# CY8C6347BZI_BLD33 register map
File version: 0.1
PSoC 63
Registers are 32-bit, read-write, no defined reset value unless marked. A register's access mark holds for its fields unless they carry their own. Offsets are from the block's base; lines under a group give offsets from that group; [hi:lo] are bit positions; {n}, {i} and the like mark numbered series; 'fields as' and 'values as' point back to an identical list; <NAME> marks a mode.

## Memory map
0x00000000 SMIF_1
0x00000000 CapSense

## SMIF_1
Base 0x00000000
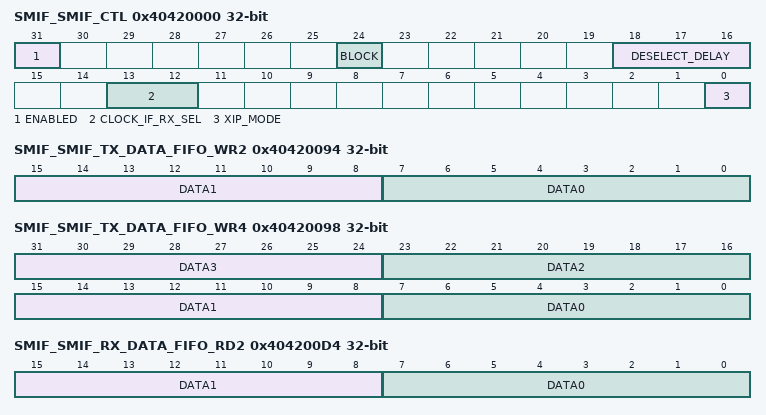
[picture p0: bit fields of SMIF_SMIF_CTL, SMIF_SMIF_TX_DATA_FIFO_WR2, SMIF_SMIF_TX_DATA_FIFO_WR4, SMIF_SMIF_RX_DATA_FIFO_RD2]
0x40420000 SMIF_SMIF_CTL — Control
  [31] ENABLED — IP enable:?'0': Disabled. All non-retention registers are reset to their default value when the IP is disabled. When the IP is disabled, the XIP accesses produce AHB-Lite bus errors.?'1': Enabled.??Note: Before disabling the IP, SW should ensure that the IP is NOT busy (STATUS.BUSY is '0'), otherwise illegal interface transfers may occur.
    0=DISABLED; 1=ENABLED
  [24] BLOCK — Specifies what happens for MMIO interface read accesses to an empty RX data FIFO or to a full TX format/data FIFO. Note: the FIFOs can only be accessed in MMIO_MODE.??This field is not used for test controller accesses.
    0=BUS_ERROR (0': Generate an AHB-Lite bus error. This option is useful when SW decides to use polling on STATUS.TR_BUSY to determine if a interface transfer is no longer busy (transfer is completed). This option adds SW complexity, but limits the number of AHB-Lite wait states (and limits ISR latency).); 1=WAIT_STATES (1': Introduce wait states. This setting potentially locks up the AHB-Lite infrastructure and may increase the CPU interrupt latency.This option is useful when SW performs TX/RX data FIFO accesses immediately after a command is setup using the TX format FIFO. This option has low SW complexity, but may result in a significant number of AHB-Lite wait states (and may increase ISR latency).)
  [18:16] DESELECT_DELAY — Specifies the minimum duration of SPI deselection ("spi_select_out[]" is high/'1') in between SPI transfers:?"0": 1 interface clock cycle.?"1": 2 interface clock cycles.?"2": 3 interface clock cycles.?"3": 4 interface clock cycles.?"4": 5 interface clock cycles.?"5": 6 interface clock cycles.?"6": 7 interface clock cycles.?"7": 8 interface clock cycles.??During SPI deselection, "spi_select_out[]" are '1'/inactive, "spi_data_out[]" are '1' and "spi_clk_out" is '0'/inactive.
  [13:12] CLOCK_IF_RX_SEL — Specifies device interface receiver clock "clk_if_rx" source. MISO data is captured on the rising edge of "clk_if_rx".?"0": "spi_clk_out" (internal clock)?"1": !"spi_clk_out" (internal clock)?"2": "spi_clk_in" (feedback clock)?"3": !"spi_clk_in" (feedback clock)??Note: the device interface transmitter clock "clk_if_tx" is fixed and is "spi_clk_out" MOSI data is driven on the falling edge of "clk_if_tx".
  [0] XIP_MODE — Mode of operation.??Note: this field should only be changed when the IP is disabled or when STATUS.BUSY is '0' and SW should not be executing from the XIP interface or MMIO interface.
    0=MMIO_MODE ('0': MMIO mode. Individual MMIO accesses to TX and RX FIFOs are used to generate a sequence of SPI transfers. This mode of operation allows for large flexibility in terms of the SPI transfers that can be generated.); 1=XIP_MODE (1': XIP mode. eXecute-In-Place mode: incoming read and write transfers over the AHB-Lite bus infrastructure are automatically translated in SPI transfers to read data from and write data to a device. This mode of operation allow for efficient device read and write operations. This mode is only supported in SPI_MODE.)
0x40420004 SMIF_SMIF_STATUS — Status
  [31] BUSY ro — Cache, cryptography, XIP, device interface or any other logic busy in the IP:?'0': not busy?'1': busy?When BUSY is '0', the IP can be safely disabled without:?- the potential loss of transient write data.?- the potential risk of aborting an inflight SPI device interface transfer.?When BUSY is '0', the mode of operation (XIP_MODE or MMIO_MODE) can be safely changed.
0x40420044 SMIF_SMIF_TX_CMD_FIFO_STATUS — Transmitter command FIFO status
  [2:0] USED3 ro — Number of entries that are used in the TX command FIFO (available in both XIP_MODE and MMIO_MODE). Legal range: [0, 4].
0x40420050 SMIF_SMIF_TX_CMD_FIFO_WR — Transmitter command FIFO write
  [19:0] DATA20 wo — Command data. The higher two bits DATA[19:18] specify the specific command?"0"/TX: A SPI transfer always start with a TX command FIFO entry of the ?TX? format.?- DATA[17:16] specifies the width of the data transfer:? - "0": 1 bit/cycle (single data transfer).? - "1": 2 bits/cycle (dual data transfer).? - "2": 4 bits/cycle (quad data transfer).? - "3": 8 bits/cycle (octal data transfer).?- DATA[15]: specifies whether this is the last TX Byte; i.e. whether the ?spi_select_out[3:0]? IO output signals are de-activated after the transfer.?- DATA[11:8] specifies which of the four devices are selected. DATA[11:8] are directly mapped to "spi_select_out[3:0]". Two devices can be selected at the same time in dual-quad mode.? - '0': device deselected? - '1': device selected ?- DATA[7:0] specifies the transmitted Byte.??"1"/TX_COUNT: The ?TX_COUNT? command relies on the TX data FIFO to provide the transmitted bytes. The "TX_COUNT" command is ALWAYS considered to be the last command of a SPI data transfers.?- DATA[17:16] specifies the width of the transfer.?- DATA[15:0] specifies the number of to be transmitted Bytes (minus 1) from the TX data FIFO.??"2"/RX_COUNT: The ?RX_COUNT? command relies on the RX data FIFO to accept the received bytes. The "RX_COUNT" command is ALWAYS considered to be the last command of a SPI data transfers.?- DATA[17:16] specifies the width of the transfer.?- DATA[15:0] specifies the number of to be transmitted Bytes (minus 1) to the RX data FIFO.??"3"/DUMMY_COUNT: The "DUMMY_COUNT" command conveys dummy cycles. Dummy cycles are used to implement a Turn-Around time in which the SPI master changes from a transmitter driving the data lines to a receiver receiving on the same data lines. The "DUMMY_COUNT" command is ALWAYS considered to be NOT the last command of a SPI data transfers; i.e. it needs to be followed by another command.?- DATA[15:0] specifies the number of dummy cycles (minus 1). In dummy cycles, the data lines are not driven.
0x40420080 SMIF_SMIF_TX_DATA_FIFO_CTL — Transmitter data FIFO control
  [2:0] TRIGGER_LEVEL — Determines when the TX data FIFO "tr_tx_req" trigger is activated (trigger activation requires MMIO_MODE, the trigger is NOT activated in XIP_MODE):?- Trigger is active when TX_DATA_FIFO_STATUS.USED <= TRIGGER_LEVEL.
0x40420084 SMIF_SMIF_TX_DATA_FIFO_STATUS — Transmitter data FIFO status
  [3:0] USED4 ro — Number of entries that are used in the TX data FIFO (available in both XIP_MODE and MMIO_MODE). Legal range: [0, 8].
0x40420090 SMIF_SMIF_TX_DATA_FIFO_WR1 — Transmitter data FIFO write
  [7:0] DATA0 wo — TX data (written to TX data FIFO).
0x40420094 SMIF_SMIF_TX_DATA_FIFO_WR2 — Transmitter data FIFO write
  [15:8] DATA1 wo — TX data (written to TX data FIFO, second byte).
  [7:0] DATA0 wo — TX data (written to TX data FIFO, first byte).
0x40420098 SMIF_SMIF_TX_DATA_FIFO_WR4 — Transmitter data FIFO write
  [31:24] DATA3 wo — TX data (written to TX data FIFO, fourth byte).
  [23:16] DATA2 wo — TX data (written to TX data FIFO, third byte).
  [15:8] DATA1 wo — TX data (written to TX data FIFO, second byte).
  [7:0] DATA0 wo — TX data (written to TX data FIFO, first byte).
0x404200C0 SMIF_SMIF_RX_DATA_FIFO_CTL — Receiver data FIFO control
  [2:0] TRIGGER_LEVEL — Determines when RX data FIFI "tr_rx_req" trigger is activated (trigger activation requires MMIO_MODE, the trigger is NOT activated in XIP_MODE):?- Trigger is active when RX_DATA_FIFO_STATUS.USED > TRIGGER_LEVEL.
0x404200C4 SMIF_SMIF_RX_DATA_FIFO_STATUS — Receiver data FIFO status
  [3:0] USED4 ro — Number of entries that are used in the RX data FIFO (available in both XIP_MODE and MMIO_MODE). Legal range: [0, 8].
0x404200D0 SMIF_SMIF_RX_DATA_FIFO_RD1 — Receiver data FIFO read
  [7:0] DATA0 ro — RX data (read from RX data FIFO).
0x404200D4 SMIF_SMIF_RX_DATA_FIFO_RD2 — Receiver data FIFO read
  [15:8] DATA1 ro — RX data (read from RX data FIFO, second byte).
  [7:0] DATA0 ro — RX data (read from RX data FIFO, first byte).
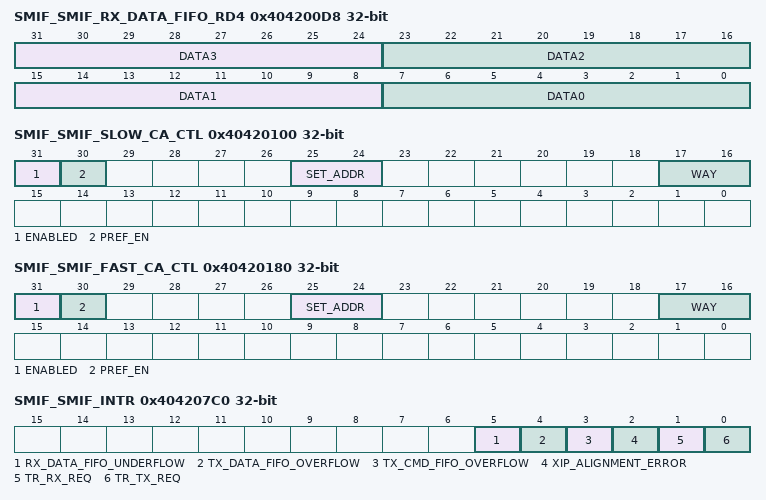
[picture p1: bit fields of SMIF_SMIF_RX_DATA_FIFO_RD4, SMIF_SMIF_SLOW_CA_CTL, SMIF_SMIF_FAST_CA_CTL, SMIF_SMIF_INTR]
0x404200D8 SMIF_SMIF_RX_DATA_FIFO_RD4 — Receiver data FIFO read
  [31:24] DATA3 ro — RX data (read from RX data FIFO, fourth byte).
  [23:16] DATA2 ro — RX data (read from RX data FIFO, third byte).
  [15:8] DATA1 ro — RX data (read from RX data FIFO, second byte).
  [7:0] DATA0 ro — RX data (read from RX data FIFO, first byte).
0x404200E0 SMIF_SMIF_RX_DATA_FIFO_RD1_SILENT — Receiver data FIFO silent read
  [7:0] DATA0 ro — RX data (read from RX data FIFO).
0x40420100 SMIF_SMIF_SLOW_CA_CTL — Slow cache control
  [31] ENABLED — Cache enable:?'0': Disabled.?'1': Enabled.
  [30] PREF_EN — Prefetch enable:?'0': Disabled.?'1': Enabled.??Prefetching requires the cache to be enabled; i.e. ENABLED is '1'.
  [25:24] SET_ADDR — Specifies the cache set for which cache information is provided in SLOW_CA_STATUS0/1/2.
  [17:16] WAY — Specifies the cache way for which cache information is provided in SLOW_CA_STATUS0/1/2.
0x40420108 SMIF_SMIF_SLOW_CA_CMD — Slow cache command
  [0] INV — Cache invalidation. SW writes a '1' to clear the cache. The cache's LRU structure is also reset to its default state.
0x40420140 SMIF_SMIF_SLOW_CA_STATUS0 — Slow cache status 0
  [15:0] VALID16 ro — Sixteen valid bits of the cache line specified by SLOW_CA_CTL.WAY and SLOW_CA_CTL.SET_ADDR.
0x40420144 SMIF_SMIF_SLOW_CA_STATUS1 — Slow cache status 1
  [31:0] TAG ro — Cache line address of the cache line specified by SLOW_CA_CTL.WAY and SLOW_CA_CTL.SET_ADDR.
0x40420148 SMIF_SMIF_SLOW_CA_STATUS2 — Slow cache status 2
  [5:0] LRU ro — Six bit LRU representation of the cache set specified by SLOW_CA_CTL.SET_ADDR. The encoding of the field is as follows ("X_LRU_Y" indicates that way X is Less Recently Used than way Y):?Bit 5: 0_LRU_1: way 0 less recently used than way 1.?Bit 4: 0_LRU_2.?Bit 3: 0_LRU_3.?Bit 2: 1_LRU_2.?Bit 1: 1_LRU_3.?Bit 0: 2_LRU_3.
0x40420180 SMIF_SMIF_FAST_CA_CTL — Fast cache control
  [31] ENABLED — See SLOW_CA_CTL.ENABLED.
  [30] PREF_EN — See SLOW_CA_CTL.PREF_EN.
  [25:24] SET_ADDR — See SLOW_CA_CTL.SET_ADDR.
  [17:16] WAY — See SLOW_CA_CTL.WAY.
0x40420188 SMIF_SMIF_FAST_CA_CMD — Fast cache command
  [0] INV — See SLOW_CA_CMD.INV.
0x404201C0 SMIF_SMIF_FAST_CA_STATUS0 — Fast cache status 0
  [15:0] VALID16 ro — See SLOW_CA_STATUS0.VALID16.
0x404201C4 SMIF_SMIF_FAST_CA_STATUS1 — Fast cache status 1
  [31:0] TAG ro — See SLOW_CA_STATUS1.TAG.
0x404201C8 SMIF_SMIF_FAST_CA_STATUS2 — Fast cache status 2
  [5:0] LRU ro — See SLOW_CA_STATUS2.LRU.
0x40420200 SMIF_SMIF_CRYPTO_CMD — Cryptography Command
  [0] START — SW sets this field to '1' to start a AES-128 forward block cipher operation (on the address in CRYPTO_ADDR). HW sets this field to '0' to indicate that the operation has completed. Once completed, the result of the operation can be read from CRYPTO_RESULT0, ..., CRYPTO_RESULT3.??The operation takes roughly 13 clk_hf clock cycles.??Note: An operation can only be started in MMIO_MODE.
{0x40420220+4i} SMIF_SMIF_CRYPTO_INPUT{i} (i=0..3) — Cryptography input {i}
  [31:0] INPUT — Four Bytes of the plaintext PT[{32i+31}:{32i}] = CRYPTO_INPUT{i}.INPUT[31:0].
{0x40420240+4i} SMIF_SMIF_CRYPTO_KEY{i} (i=0..3) — Cryptography key {i}
  [31:0] KEY wo — Four Bytes of the key KEY[{32i+31}:{32i}] = CRYPTO_KEY{i}.KEY[31:0].
{0x40420260+4i} SMIF_SMIF_CRYPTO_OUTPUT{i} (i=0..3) — Cryptography output {i}
  [31:0] OUTPUT — Four Bytes of the ciphertext CT[{32i+31}:{32i}] = CRYPTO_OUTPUT{i}.OUTPUT[31:0].
0x404207C0 SMIF_SMIF_INTR — Interrupt register
  [5] RX_DATA_FIFO_UNDERFLOW — Activated in MMIO mode, on an AHB-Lite read transfer from the RX data FIFO (RX_DATA_FIFO_RD1, RX_DATA_FIFO_RD2, RX_DATA_FIFO_RD4) with not enough entries available. Only activated for NON test bus controller transfers.
  [4] TX_DATA_FIFO_OVERFLOW — Activated in MMIO mode, on an AHB-Lite write transfer to the TX data FIFO (TX_DATA_FIFO_WR1, TX_DATA_FIFO_WR2, TX_DATA_FIFO_WR4) with not enough free entries available.
  [3] TX_CMD_FIFO_OVERFLOW — Activated in MMIO mode, on an AHB-Lite write transfer to the TX command FIFO (TX_CMD_FIFO_WR) with not enough free entries available.
  [2] XIP_ALIGNMENT_ERROR — Activated in XIP mode, if:?- The selected device's ADDR_CTL.DIV2 is '1' and the AHB-Lite bus transfer address is not a multiple of 2.?- The selected device's ADDR_CTL.DIV2 is '1' and the XIP transfer request is NOT for a multiple of 2 Bytes. ??Note: In dual-quad SPI mode (ADDR_CTL.DIV is '1'), each memory device contributes a 4-bit nibble for read data or write data. This is only possible if the request address is a multiple of 2 and the number of requested Bytes is a multiple of 2.
  [1] TR_RX_REQ — Activated in MMIO mode, when a RX data FIFO trigger "tr_rx_req" is activated.
  [0] TR_TX_REQ — Activated in MMIO mode, when a TX data FIFO trigger "tr_tx_req" is activated.
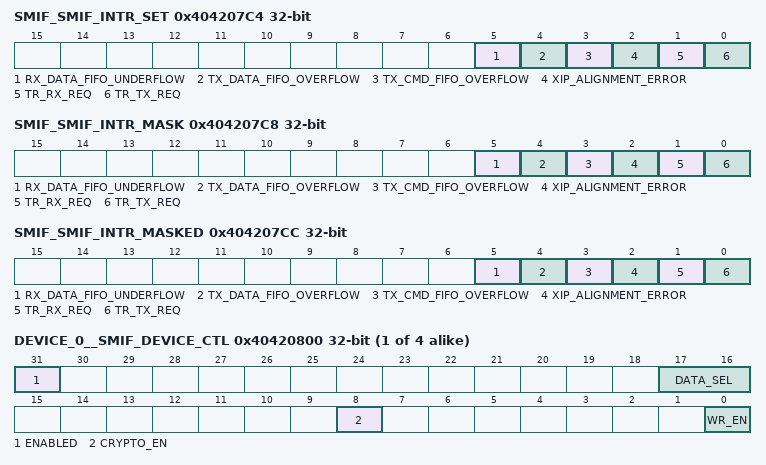
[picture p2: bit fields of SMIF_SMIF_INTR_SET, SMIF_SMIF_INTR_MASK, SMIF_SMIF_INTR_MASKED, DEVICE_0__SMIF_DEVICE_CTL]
0x404207C4 SMIF_SMIF_INTR_SET — Interrupt set register
  [5] RX_DATA_FIFO_UNDERFLOW — Write with '1' to set corresponding bit in interrupt request register.
  [4] TX_DATA_FIFO_OVERFLOW — Write with '1' to set corresponding bit in interrupt request register.
  [3] TX_CMD_FIFO_OVERFLOW — Write with '1' to set corresponding bit in interrupt request register.
  [2] XIP_ALIGNMENT_ERROR — Write with '1' to set corresponding bit in interrupt request register.
  [1] TR_RX_REQ — Write with '1' to set corresponding bit in interrupt request register.
  [0] TR_TX_REQ — Write with '1' to set corresponding bit in interrupt request register.
0x404207C8 SMIF_SMIF_INTR_MASK — Interrupt mask register
  [5] RX_DATA_FIFO_UNDERFLOW — Mask bit for corresponding bit in interrupt request register.
  [4] TX_DATA_FIFO_OVERFLOW — Mask bit for corresponding bit in interrupt request register.
  [3] TX_CMD_FIFO_OVERFLOW — Mask bit for corresponding bit in interrupt request register.
  [2] XIP_ALIGNMENT_ERROR — Mask bit for corresponding bit in interrupt request register.
  [1] TR_RX_REQ — Mask bit for corresponding bit in interrupt request register.
  [0] TR_TX_REQ — Mask bit for corresponding bit in interrupt request register.
0x404207CC SMIF_SMIF_INTR_MASKED — Interrupt masked register
  [5] RX_DATA_FIFO_UNDERFLOW ro — Logical and of corresponding request and mask bits.
  [4] TX_DATA_FIFO_OVERFLOW ro — Logical and of corresponding request and mask bits.
  [3] TX_CMD_FIFO_OVERFLOW ro — Logical and of corresponding request and mask bits.
  [2] XIP_ALIGNMENT_ERROR ro — Logical and of corresponding request and mask bits.
  [1] TR_RX_REQ ro — Logical and of corresponding request and mask bits.
  [0] TR_TX_REQ ro — Logical and of corresponding request and mask bits.
{0x40420800+0x80*i} DEVICE_{i}__SMIF_DEVICE_CTL (i=0..3) — Control
  [31] ENABLED — Device enable:?'0': Disabled.?'1': Enabled.
  [17:16] DATA_SEL — Specifies the connection of the IP's data lines (spi_data[0], ?, spi_data[7]) to the device's data lines (SI/IO0, SO/IO1, IO2, IO3, IO4, IO5, IO6, IO7):?"0": spi_data[0] = IO0, spi_data[1] = IO1, ?, spi_data[7] = IO7. This value is allowed for single, dual, quad, dual quad and octal SPI modes. This value must be used for the first device in dual quad SPI mode. This value must be used for octal SPI mode.?"1": spi_data[2] = IO0, spi_data[3] = IO1. This value is only allowed for single and dual SPI modes.?"2": spi_data[4] = IO0, spi_data[5] = IO1, ?, spi_data[7] = IO3. This value is only allowed for single, dual, quad and dual quad SPI modes. In dual quad SPI mode, this value must be used for the second device. ?"3": spi_data[6] = IO0, spi_data[7] = IO1. This value is only allowed for single and dual SPI modes.
  [8] CRYPTO_EN — Cryptography on read/write accesses:?'0': disabled.?'1': enabled.
  [0] WR_EN — Write enable:?'0': write transfers are not allowed to this device. An attempt to write to this device results in an AHB-Lite bus error.?'1': write transfers are allowed to this device.
{0x40420808+0x80*i} DEVICE_{i}__SMIF_DEVICE_ADDR (i=0..3) — Device region base address
  [31:8] ADDR — Specifies the base address of the device region. If the device region is 2^m Bytes, ADDR MUST be a multiple of 2^m.??In dual quad SPI data transfer, the two devices should have the same ADDR and MASK register settings. The device control information (ADDR_CTL, RD_CMD_CTL, etc.) are provided by the MMIO control registers of the device with the lowest index.??The most significant bit fields are constants and set based on the SMIF_XIP_ADDR parameter. The most significant bits are identified on the SMIF_XIP_MASK parameter. E.g., if SMIF_XIP_MASK is 0xff00:0000 (16 MB XIP memory region), ADDR[31:24] = SMIF_XIP_ADDR[31:24].
{0x4042080C+0x80*i} DEVICE_{i}__SMIF_DEVICE_MASK (i=0..3) — Device region mask
  [31:8] MASK — Specifies the size of the device region. All '1' bits are used to compare the incoming transfer request address A[31:0] with the address as specified in ADDR.ADDR: Address A is in the device when (A[31:8] & MASK[31:8]) == ADDR.ADDR[31:8].??The most significant bit fields are constants and set to'1'. The most significant bits are identified on the SMIF_XIP_MASK parameter. E.g., if SMIF_XIP_MASK is 0xff00:0000 (16 MB XIP memory region), MASK[31:24] = 0xff.??Note: a transfer request that is not in any device region results in an AHB-Lite bus error.
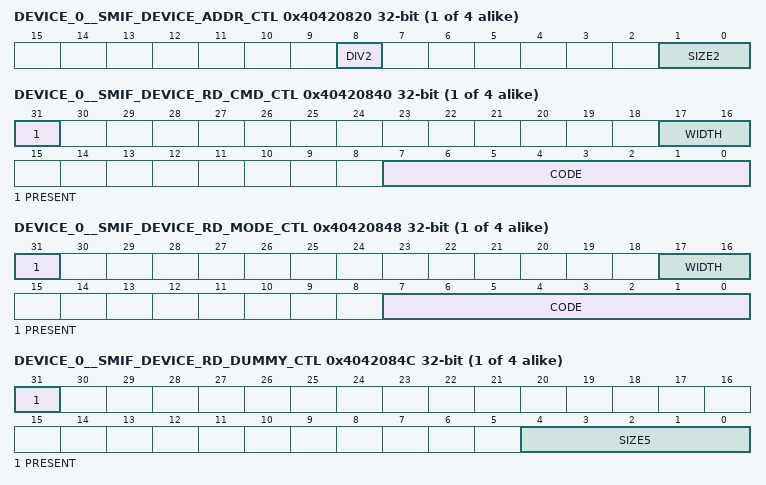
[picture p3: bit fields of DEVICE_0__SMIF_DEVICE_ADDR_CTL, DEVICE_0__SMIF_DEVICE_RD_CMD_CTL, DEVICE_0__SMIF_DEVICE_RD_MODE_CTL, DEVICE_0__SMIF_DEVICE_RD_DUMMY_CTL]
{0x40420820+0x80*i} DEVICE_{i}__SMIF_DEVICE_ADDR_CTL (i=0..3) — Address control
  [8] DIV2 — Specifies if the AHB-Lite bus transfer address is divided by 2 or not:?'0': No divide by 2.?'1': Divide by 2. ??This functionality is used for read and write operation in XIP, dual quad SPI mode; i.e. this DIV2 must be set to '1' in dual quad SPI mode. If the transfer request address is NOT a multiple of 2 or the requested number of Bytes is not a multiple of 2, the XIP_ALIGNMENT_ERROR interrupt cause is activated.
  [1:0] SIZE2 — Specifies the size of the XIP device address in Bytes:?"0": 1 Byte address.?"1": 2 Byte address.?"2": 3 Byte address.?"3": 4 Byte address.?The lower significant address Bytes of the transfer request are used as XIP address to the external device. Note that for dual quad SPI data transfer, the transfer request address is divided by 2. Therefore, the transfer request address needs to be a multiple of 2. If the trasnfer requestaddress is NOT a multiple of 2, the XIP_ALIGNMENT_ERROR interrupt cause is activated.
{0x40420840+0x80*i} DEVICE_{i}__SMIF_DEVICE_RD_CMD_CTL (i=0..3) — Read command control
  [31] PRESENT — Presence of command field:?'0': not present?'1': present
  [17:16] WIDTH — Width of data transfer:?"0": 1 bit/cycle (single data transfer).?"1": 2 bits/cycle (dual data transfer).?"2": 4 bits/cycle (quad data transfer).?"3": 8 bits/cycle (octal data transfer).
  [7:0] CODE — Command byte code.
{0x40420844+0x80*i} DEVICE_{i}__SMIF_DEVICE_RD_ADDR_CTL (i=0..3) — Read address control
  [17:16] WIDTH — Width of transfer.
{0x40420848+0x80*i} DEVICE_{i}__SMIF_DEVICE_RD_MODE_CTL (i=0..3) — Read mode control
  [31] PRESENT — Presence of mode field:?'0': not present?'1': present
  [17:16] WIDTH — Width of transfer.
  [7:0] CODE — Mode byte code.
{0x4042084C+0x80*i} DEVICE_{i}__SMIF_DEVICE_RD_DUMMY_CTL (i=0..3) — Read dummy control
  [31] PRESENT — Presence of dummy cycles:?'0': not present?'1': present
  [4:0] SIZE5 — Number of dummy cycles (minus 1):?"0": 1 cycles?...?"31": 32 cycles.??Note: this field specifies dummy cycles, not dummy Bytes!
{0x40420850+0x80*i} DEVICE_{i}__SMIF_DEVICE_RD_DATA_CTL (i=0..3) — Read data control
  [17:16] WIDTH — Width of transfer.
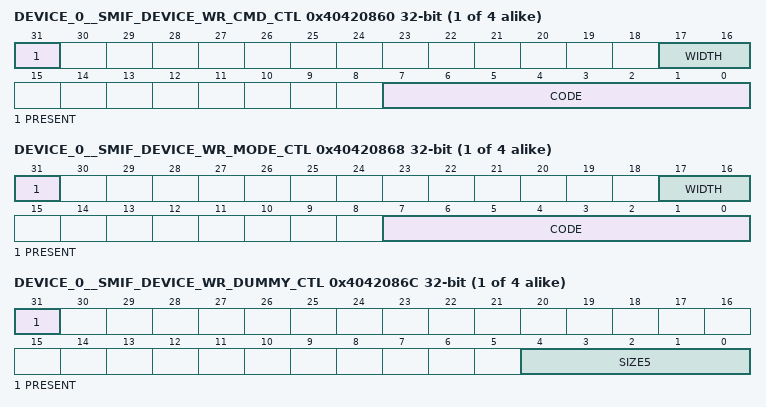
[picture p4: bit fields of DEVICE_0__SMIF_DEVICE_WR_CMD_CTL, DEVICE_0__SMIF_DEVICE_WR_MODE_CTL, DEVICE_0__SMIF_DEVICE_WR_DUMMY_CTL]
{0x40420860+0x80*i} DEVICE_{i}__SMIF_DEVICE_WR_CMD_CTL (i=0..3) — Write command control
  [31] PRESENT — Presence of command field:?'0': not present?'1': present
  [17:16] WIDTH — Width of transfer.
  [7:0] CODE — Command byte code.
{0x40420864+0x80*i} DEVICE_{i}__SMIF_DEVICE_WR_ADDR_CTL (i=0..3) — Write address control
  [17:16] WIDTH — Width of transfer.
{0x40420868+0x80*i} DEVICE_{i}__SMIF_DEVICE_WR_MODE_CTL (i=0..3) — Write mode control
  fields as DEVICE_0__SMIF_DEVICE_RD_MODE_CTL
{0x4042086C+0x80*i} DEVICE_{i}__SMIF_DEVICE_WR_DUMMY_CTL (i=0..3) — Write dummy control
  [31] PRESENT — Presence of dummy cycles:?'0': not present?'1': present
  [4:0] SIZE5 — Number of dummy cycles (minus 1):?"0": 1 cycles?...?"31": 32 cycles.
{0x40420870+0x80*i} DEVICE_{i}__SMIF_DEVICE_WR_DATA_CTL (i=0..3) — Write data control
  [17:16] WIDTH — Width of transfer.
